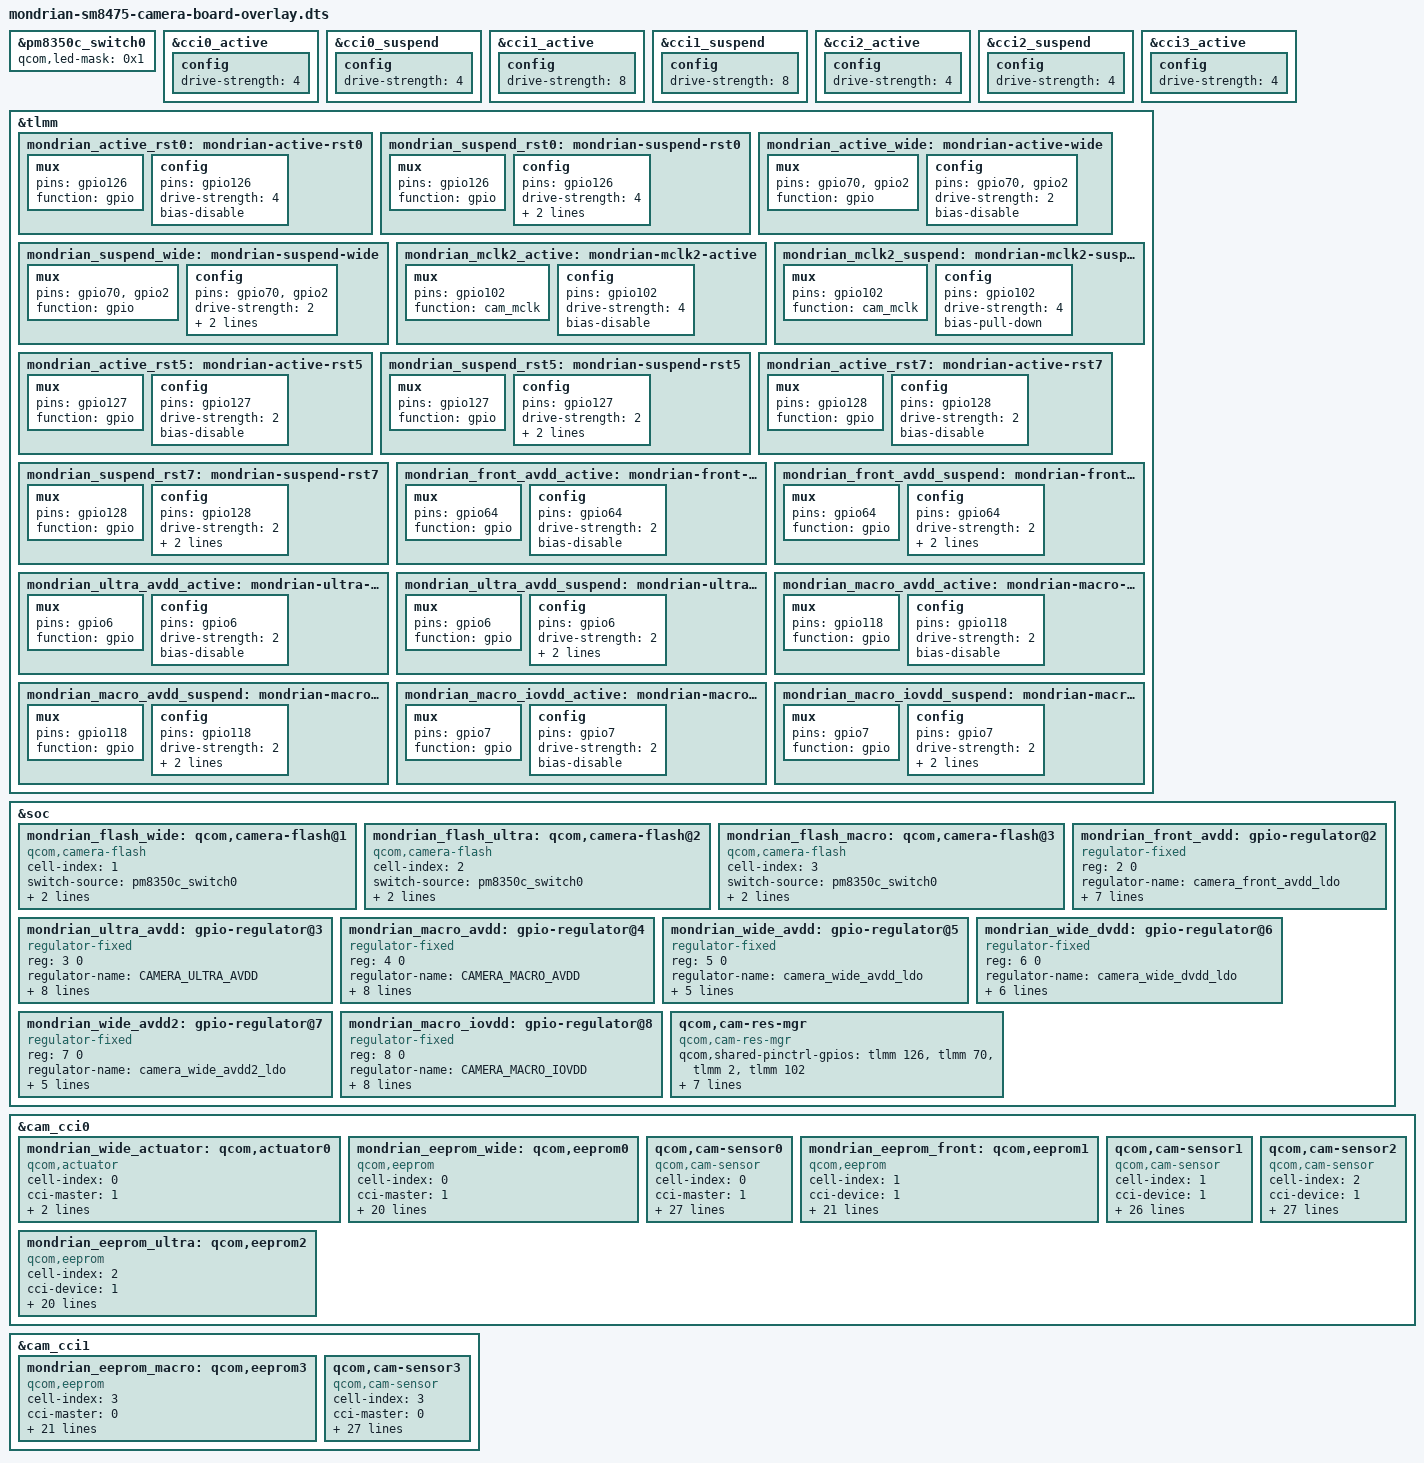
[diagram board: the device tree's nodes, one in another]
// SPDX-License-Identifier: GPL-2.0-only
/dts-v1/;
/plugin/;

#include <dt-bindings/clock/qcom,camcc-waipio.h>

/* Diagnostic board layer, applied after the OEM mondrian board and Cape camera
 * controllers. The board routes and evidence are documented in
 * docs/MONDRIAN_STOCK_CAMERA_ROUTING.md.
 */

&pm8350c_switch0 {
	qcom,led-mask = <0x1>;
};

&cci0_active {
	config {
		drive-strength = <4>;
	};
};

&cci0_suspend {
	config {
		drive-strength = <4>;
	};
};

&cci1_active {
	config {
		drive-strength = <8>;
	};
};

&cci1_suspend {
	config {
		drive-strength = <8>;
	};
};

&cci2_active {
	config {
		drive-strength = <4>;
	};
};

&cci2_suspend {
	config {
		drive-strength = <4>;
	};
};

&cci3_active {
	config {
		drive-strength = <4>;
	};
};

&tlmm {
	mondrian_active_rst0: mondrian-active-rst0 {
		mux {
			pins = "gpio126";
			function = "gpio";
		};
		config {
			pins = "gpio126";
			drive-strength = <4>;
			bias-disable;
		};
	};

	mondrian_suspend_rst0: mondrian-suspend-rst0 {
		mux {
			pins = "gpio126";
			function = "gpio";
		};
		config {
			pins = "gpio126";
			drive-strength = <4>;
			bias-pull-down;
			output-low;
		};
	};

	mondrian_active_wide: mondrian-active-wide {
		mux {
			pins = "gpio70", "gpio2";
			function = "gpio";
		};
		config {
			pins = "gpio70", "gpio2";
			drive-strength = <2>;
			bias-disable;
		};
	};

	mondrian_suspend_wide: mondrian-suspend-wide {
		mux {
			pins = "gpio70", "gpio2";
			function = "gpio";
		};
		config {
			pins = "gpio70", "gpio2";
			drive-strength = <2>;
			bias-pull-down;
			output-low;
		};
	};

	mondrian_mclk2_active: mondrian-mclk2-active {
		mux {
			pins = "gpio102";
			function = "cam_mclk";
		};
		config {
			pins = "gpio102";
			drive-strength = <4>;
			bias-disable;
		};
	};

	mondrian_mclk2_suspend: mondrian-mclk2-suspend {
		mux {
			pins = "gpio102";
			function = "cam_mclk";
		};
		config {
			pins = "gpio102";
			drive-strength = <4>;
			bias-pull-down;
		};
	};

	mondrian_active_rst5: mondrian-active-rst5 {
		mux {
			pins = "gpio127";
			function = "gpio";
		};
		config {
			pins = "gpio127";
			drive-strength = <2>;
			bias-disable;
		};
	};

	mondrian_suspend_rst5: mondrian-suspend-rst5 {
		mux {
			pins = "gpio127";
			function = "gpio";
		};
		config {
			pins = "gpio127";
			drive-strength = <2>;
			bias-pull-down;
			output-low;
		};
	};

	mondrian_active_rst7: mondrian-active-rst7 {
		mux {
			pins = "gpio128";
			function = "gpio";
		};
		config {
			pins = "gpio128";
			drive-strength = <2>;
			bias-disable;
		};
	};

	mondrian_suspend_rst7: mondrian-suspend-rst7 {
		mux {
			pins = "gpio128";
			function = "gpio";
		};
		config {
			pins = "gpio128";
			drive-strength = <2>;
			bias-pull-down;
			output-low;
		};
	};

	mondrian_front_avdd_active: mondrian-front-avdd-active {
		mux {
			pins = "gpio64";
			function = "gpio";
		};
		config {
			pins = "gpio64";
			drive-strength = <2>;
			bias-disable;
		};
	};

	mondrian_front_avdd_suspend: mondrian-front-avdd-suspend {
		mux {
			pins = "gpio64";
			function = "gpio";
		};
		config {
			pins = "gpio64";
			drive-strength = <2>;
			bias-pull-down;
			output-low;
		};
	};

	mondrian_ultra_avdd_active: mondrian-ultra-avdd-active {
		mux {
			pins = "gpio6";
			function = "gpio";
		};
		config {
			pins = "gpio6";
			drive-strength = <2>;
			bias-disable;
		};
	};

	mondrian_ultra_avdd_suspend: mondrian-ultra-avdd-suspend {
		mux {
			pins = "gpio6";
			function = "gpio";
		};
		config {
			pins = "gpio6";
			drive-strength = <2>;
			bias-pull-down;
			output-low;
		};
	};

	mondrian_macro_avdd_active: mondrian-macro-avdd-active {
		mux {
			pins = "gpio118";
			function = "gpio";
		};
		config {
			pins = "gpio118";
			drive-strength = <2>;
			bias-disable;
		};
	};

	mondrian_macro_avdd_suspend: mondrian-macro-avdd-suspend {
		mux {
			pins = "gpio118";
			function = "gpio";
		};
		config {
			pins = "gpio118";
			drive-strength = <2>;
			bias-pull-down;
			output-low;
		};
	};

	/* Macro IOVDD switch on GPIO 7, as in the stock OS3 mondrian DT. */
	mondrian_macro_iovdd_active: mondrian-macro-iovdd-active {
		mux {
			pins = "gpio7";
			function = "gpio";
		};
		config {
			pins = "gpio7";
			drive-strength = <2>;
			bias-disable;
		};
	};

	mondrian_macro_iovdd_suspend: mondrian-macro-iovdd-suspend {
		mux {
			pins = "gpio7";
			function = "gpio";
		};
		config {
			pins = "gpio7";
			drive-strength = <2>;
			bias-pull-down;
			output-low;
		};
	};
};

&soc {
	mondrian_flash_wide: qcom,camera-flash@1 {
		compatible = "qcom,camera-flash";
		cell-index = <1>;
		switch-source = <&pm8350c_switch0>;
		flash-source = <&pm8350c_flash0>;
		torch-source = <&pm8350c_torch0>;
		status = "ok";
	};

	mondrian_flash_ultra: qcom,camera-flash@2 {
		compatible = "qcom,camera-flash";
		cell-index = <2>;
		switch-source = <&pm8350c_switch0>;
		flash-source = <&pm8350c_flash0>;
		torch-source = <&pm8350c_torch0>;
		status = "ok";
	};

	mondrian_flash_macro: qcom,camera-flash@3 {
		compatible = "qcom,camera-flash";
		cell-index = <3>;
		switch-source = <&pm8350c_switch0>;
		flash-source = <&pm8350c_flash0>;
		torch-source = <&pm8350c_torch0>;
		status = "ok";
	};

	mondrian_front_avdd: gpio-regulator@2 {
		compatible = "regulator-fixed";
		reg = <2 0>;
		regulator-name = "camera_front_avdd_ldo";
		regulator-min-microvolt = <2800000>;
		regulator-max-microvolt = <2800000>;
		regulator-enable-ramp-delay = <100>;
		gpio = <&tlmm 64 0>;
		enable-active-high;
		pinctrl-names = "front_avdd_active", "front_avdd_suspend";
		pinctrl-0 = <&mondrian_front_avdd_active>, <&mondrian_front_avdd_suspend>;
	};

	mondrian_ultra_avdd: gpio-regulator@3 {
		compatible = "regulator-fixed";
		reg = <3 0>;
		regulator-name = "CAMERA_ULTRA_AVDD";
		regulator-min-microvolt = <2800000>;
		regulator-max-microvolt = <2800000>;
		regulator-enable-ramp-delay = <100>;
		vin-supply = <&BOB>;
		gpio = <&tlmm 6 0>;
		enable-active-high;
		pinctrl-names = "ultra_avdd_active", "ultra_avdd_suspend";
		pinctrl-0 = <&mondrian_ultra_avdd_active>, <&mondrian_ultra_avdd_suspend>;
	};

	mondrian_macro_avdd: gpio-regulator@4 {
		compatible = "regulator-fixed";
		reg = <4 0>;
		regulator-name = "CAMERA_MACRO_AVDD";
		regulator-min-microvolt = <2800000>;
		regulator-max-microvolt = <2800000>;
		regulator-enable-ramp-delay = <100>;
		vin-supply = <&BOB>;
		gpio = <&tlmm 118 0>;
		enable-active-high;
		pinctrl-names = "macro_avdd_active", "macro_avdd_suspend";
		pinctrl-0 = <&mondrian_macro_avdd_active>, <&mondrian_macro_avdd_suspend>;
	};

	mondrian_wide_avdd: gpio-regulator@5 {
		compatible = "regulator-fixed";
		reg = <5 0>;
		regulator-name = "camera_wide_avdd_ldo";
		regulator-min-microvolt = <2800000>;
		regulator-max-microvolt = <2800000>;
		regulator-enable-ramp-delay = <100>;
		gpio = <&tlmm 70 0>;
		enable-active-high;
	};

	mondrian_wide_dvdd: gpio-regulator@6 {
		compatible = "regulator-fixed";
		reg = <6 0>;
		regulator-name = "camera_wide_dvdd_ldo";
		regulator-min-microvolt = <1100000>;
		regulator-max-microvolt = <1100000>;
		regulator-enable-ramp-delay = <100>;
		vin-supply = <&S12B>;
		gpio = <&tlmm 2 0>;
		enable-active-high;
	};

	mondrian_wide_avdd2: gpio-regulator@7 {
		compatible = "regulator-fixed";
		reg = <7 0>;
		regulator-name = "camera_wide_avdd2_ldo";
		regulator-min-microvolt = <1860000>;
		regulator-max-microvolt = <1860000>;
		regulator-enable-ramp-delay = <100>;
		gpio = <&tlmm 97 0>;
		enable-active-high;
	};

	/*
	 * CAMERA_MACRO_IOVDD (GPIO 7 switch from BOB), as in the stock OS3
	 * mondrian DT. No sensor uses it (the macro sensor's cam_vio is
	 * pm8350c L1), so the regulator core turns it off as unused at late
	 * init, exactly as on stock, instead of leaving GPIO 7 as the
	 * bootloader set it.
	 */
	mondrian_macro_iovdd: gpio-regulator@8 {
		compatible = "regulator-fixed";
		reg = <8 0>;
		regulator-name = "CAMERA_MACRO_IOVDD";
		regulator-min-microvolt = <1800000>;
		regulator-max-microvolt = <1800000>;
		regulator-enable-ramp-delay = <100>;
		vin-supply = <&BOB>;
		gpio = <&tlmm 7 0>;
		enable-active-high;
		pinctrl-names = "macro_iovdd_active", "macro_iovdd_suspend";
		pinctrl-0 = <&mondrian_macro_iovdd_active>, <&mondrian_macro_iovdd_suspend>;
	};

	/* GPIO specifiers are resolved by the camera resource manager at probe. */
	qcom,cam-res-mgr {
		compatible = "qcom,cam-res-mgr";
		qcom,shared-pinctrl-gpios = <&tlmm 126 0>, <&tlmm 70 0>, <&tlmm 2 0>, <&tlmm 102 0>;
		shared-pctrl-gpio-names = "cam_wide", "cam_wide", "cam_wide", "cam_wide";
		pinctrl-names = "cam_wide_active", "cam_wide_suspend";
		pinctrl-0 = <&mondrian_active_rst0>, <&mondrian_active_wide>, <&mondrian_mclk2_active>;
		pinctrl-1 = <&mondrian_suspend_rst0>, <&mondrian_suspend_wide>, <&mondrian_mclk2_suspend>;
		status = "ok";
	};
};

&cam_cci0 {
	mondrian_wide_actuator: qcom,actuator0 {
		compatible = "qcom,actuator";
		cell-index = <0>;
		cci-master = <1>;
		regulator-names = "cam_vdig";
		cam_vdig-supply = <&mondrian_wide_dvdd>;
	};

	mondrian_eeprom_wide: qcom,eeprom0 {
		compatible = "qcom,eeprom";
		cell-index = <0>;
		cci-master = <1>;
		regulator-names = "cam_vdig", "cam_clk", "cam_vana", "cam_v_custom1";
		cam_vdig-supply = <&mondrian_wide_dvdd>;
		cam_vana-supply = <&mondrian_wide_avdd>;
		cam_v_custom1-supply = <&mondrian_wide_avdd2>;
		cam_clk-supply = <&cam_cc_titan_top_gdsc>;
		rgltr-cntrl-support;
		rgltr-min-voltage = <1100000 0 2800000 1860000>;
		rgltr-max-voltage = <1100000 0 2800000 1860000>;
		rgltr-load-current = <680000 0 103000 50000>;
		clock-names = "cam_clk";
		clocks = <&clock_camcc CAM_CC_MCLK2_CLK>;
		clock-rates = <19200000>;
		clock-cntl-level = "nominal";
		use-shared-clk;
		gpios = <&tlmm 102 0>, <&tlmm 126 0>;
		gpio-no-mux = <0>;
		gpio-reset = <1>;
		gpio-req-tbl-num = <0 1>;
		gpio-req-tbl-flags = <1 0>;
		gpio-req-tbl-label = "CAMIF_MCLK2", "CAM_RESET0";
		status = "ok";
	};

	qcom,cam-sensor0 {
		compatible = "qcom,cam-sensor";
		cell-index = <0>;
		cci-master = <1>;
		csiphy-sd-index = <2>;
		eeprom-src = <&mondrian_eeprom_wide>;
		actuator-src = <&mondrian_wide_actuator>;
		led-flash-src = <&mondrian_flash_wide>;
		sensor-position-roll = <90>;
		sensor-position-pitch = <0>;
		sensor-position-yaw = <180>;
		regulator-names = "cam_vdig", "cam_clk", "cam_vana", "cam_v_custom1";
		cam_vdig-supply = <&mondrian_wide_dvdd>;
		cam_vana-supply = <&mondrian_wide_avdd>;
		cam_v_custom1-supply = <&mondrian_wide_avdd2>;
		cam_clk-supply = <&cam_cc_titan_top_gdsc>;
		rgltr-cntrl-support;
		rgltr-min-voltage = <1100000 0 2800000 1860000>;
		rgltr-max-voltage = <1100000 0 2800000 1860000>;
		rgltr-load-current = <680000 0 103000 50000>;
		clock-names = "cam_clk";
		clocks = <&clock_camcc CAM_CC_MCLK2_CLK>;
		clock-rates = <19200000>;
		clock-cntl-level = "nominal";
		use-shared-clk;
		gpios = <&tlmm 102 0>, <&tlmm 126 0>;
		gpio-no-mux = <0>;
		gpio-reset = <1>;
		gpio-req-tbl-num = <0 1>;
		gpio-req-tbl-flags = <1 0>;
		gpio-req-tbl-label = "CAMIF_MCLK2", "CAM_RESET0";
		status = "ok";
	};

	mondrian_eeprom_front: qcom,eeprom1 {
		compatible = "qcom,eeprom";
		cell-index = <1>;
		cci-device = <1>;
		cci-master = <0>;
		regulator-names = "cam_clk", "cam_vana";
		cam_vana-supply = <&mondrian_front_avdd>;
		cam_clk-supply = <&cam_cc_titan_top_gdsc>;
		rgltr-cntrl-support;
		rgltr-min-voltage = <0 2800000>;
		rgltr-max-voltage = <0 2800000>;
		rgltr-load-current = <0 35000>;
		clock-names = "cam_clk";
		clocks = <&clock_camcc CAM_CC_MCLK5_CLK>;
		clock-rates = <19200000>;
		clock-cntl-level = "nominal";
		gpios = <&tlmm 105 0>, <&tlmm 127 0>;
		gpio-no-mux = <0>;
		gpio-reset = <1>;
		gpio-req-tbl-num = <0 1>;
		gpio-req-tbl-flags = <1 0>;
		gpio-req-tbl-label = "CAMIF_MCLK5", "CAM_RESET5";
		pinctrl-names = "cam_default", "cam_suspend";
		pinctrl-0 = <&cam_sensor_mclk5_active>, <&mondrian_active_rst5>;
		pinctrl-1 = <&cam_sensor_mclk5_suspend>, <&mondrian_suspend_rst5>;
		status = "ok";
	};

	qcom,cam-sensor1 {
		compatible = "qcom,cam-sensor";
		cell-index = <1>;
		cci-device = <1>;
		cci-master = <0>;
		csiphy-sd-index = <4>;
		eeprom-src = <&mondrian_eeprom_front>;
		sensor-position-roll = <270>;
		sensor-position-pitch = <0>;
		sensor-position-yaw = <0>;
		regulator-names = "cam_clk", "cam_vana";
		cam_vana-supply = <&mondrian_front_avdd>;
		cam_clk-supply = <&cam_cc_titan_top_gdsc>;
		rgltr-cntrl-support;
		rgltr-min-voltage = <0 2800000>;
		rgltr-max-voltage = <0 2800000>;
		rgltr-load-current = <0 35000>;
		clock-names = "cam_clk";
		clocks = <&clock_camcc CAM_CC_MCLK5_CLK>;
		clock-rates = <19200000>;
		clock-cntl-level = "nominal";
		gpios = <&tlmm 105 0>, <&tlmm 127 0>;
		gpio-no-mux = <0>;
		gpio-reset = <1>;
		gpio-req-tbl-num = <0 1>;
		gpio-req-tbl-flags = <1 0>;
		gpio-req-tbl-label = "CAMIF_MCLK5", "CAM_RESET5";
		pinctrl-names = "cam_default", "cam_suspend";
		pinctrl-0 = <&cam_sensor_mclk5_active>, <&mondrian_active_rst5>;
		pinctrl-1 = <&cam_sensor_mclk5_suspend>, <&mondrian_suspend_rst5>;
		status = "ok";
	};

	/* P24C64F uses WL2866D AVDD1. GPIO index 0 is OV08D10 MCLK1. */
	mondrian_eeprom_ultra: qcom,eeprom2 {
		compatible = "qcom,eeprom";
		cell-index = <2>;
		cci-device = <1>;
		cci-master = <0>;
		regulator-names = "cam_vana", "cam_clk";
		cam_vana-supply = <&mondrian_ultra_avdd>;
		cam_clk-supply = <&cam_cc_titan_top_gdsc>;
		rgltr-cntrl-support;
		rgltr-min-voltage = <2800000 0>;
		rgltr-max-voltage = <2800000 0>;
		rgltr-load-current = <35000 0>;
		clock-names = "cam_clk";
		clocks = <&clock_camcc CAM_CC_MCLK1_CLK>;
		clock-rates = <19200000>;
		clock-cntl-level = "nominal";
		gpios = <&tlmm 101 0>, <&tlmm 24 0>;
		gpio-no-mux = <0>;
		gpio-req-tbl-num = <0 1>;
		gpio-req-tbl-flags = <1 0>;
		gpio-req-tbl-label = "CAMIF_MCLK1", "CAM_RESET1";
		pinctrl-names = "cam_default", "cam_suspend";
		pinctrl-0 = <&cam_sensor_mclk1_active>, <&cam_sensor_active_rst1>;
		pinctrl-1 = <&cam_sensor_mclk1_suspend>, <&cam_sensor_suspend_rst1>;
		status = "ok";
	};

	qcom,cam-sensor2 {
		compatible = "qcom,cam-sensor";
		cell-index = <2>;
		cci-device = <1>;
		cci-master = <0>;
		csiphy-sd-index = <1>;
		eeprom-src = <&mondrian_eeprom_ultra>;
		led-flash-src = <&mondrian_flash_ultra>;
		sensor-position-roll = <90>;
		sensor-position-pitch = <0>;
		sensor-position-yaw = <180>;
		regulator-names = "cam_clk", "cam_vana";
		cam_vana-supply = <&mondrian_ultra_avdd>;
		cam_clk-supply = <&cam_cc_titan_top_gdsc>;
		rgltr-cntrl-support;
		rgltr-min-voltage = <0 2800000>;
		rgltr-max-voltage = <0 2800000>;
		rgltr-load-current = <0 35000>;
		clock-names = "cam_clk";
		clocks = <&clock_camcc CAM_CC_MCLK1_CLK>;
		clock-rates = <19200000>;
		clock-cntl-level = "nominal";
		gpios = <&tlmm 101 0>, <&tlmm 24 0>;
		gpio-no-mux = <0>;
		gpio-reset = <1>;
		gpio-req-tbl-num = <0 1>;
		gpio-req-tbl-flags = <1 0>;
		gpio-req-tbl-label = "CAMIF_MCLK1", "CAM_RESET1";
		pinctrl-names = "cam_default", "cam_suspend";
		pinctrl-0 = <&cam_sensor_mclk1_active>, <&cam_sensor_active_rst1>;
		pinctrl-1 = <&cam_sensor_mclk1_suspend>, <&cam_sensor_suspend_rst1>;
		status = "ok";
	};
};

&cam_cci1 {
	mondrian_eeprom_macro: qcom,eeprom3 {
		compatible = "qcom,eeprom";
		cell-index = <3>;
		cci-master = <0>;
		regulator-names = "cam_vio", "cam_clk";
		cam_vana-supply = <&mondrian_macro_avdd>;
		cam_vio-supply = <&L1C>;
		cam_clk-supply = <&cam_cc_titan_top_gdsc>;
		rgltr-cntrl-support;
		rgltr-min-voltage = <1800000 0>;
		rgltr-max-voltage = <1800000 0>;
		rgltr-load-current = <5000 0>;
		clock-names = "cam_clk";
		clocks = <&clock_camcc CAM_CC_MCLK0_CLK>;
		clock-rates = <19200000>;
		clock-cntl-level = "nominal";
		gpios = <&tlmm 100 0>, <&tlmm 128 0>;
		gpio-no-mux = <0>;
		gpio-reset = <1>;
		gpio-req-tbl-num = <0 1>;
		gpio-req-tbl-flags = <1 0>;
		gpio-req-tbl-label = "CAMIF_MCLK0", "CAM_RESET7";
		pinctrl-names = "cam_default", "cam_suspend";
		pinctrl-0 = <&cam_sensor_mclk0_active>, <&mondrian_active_rst7>;
		pinctrl-1 = <&cam_sensor_mclk0_suspend>, <&mondrian_suspend_rst7>;
		status = "ok";
	};

	qcom,cam-sensor3 {
		compatible = "qcom,cam-sensor";
		cell-index = <3>;
		cci-master = <0>;
		csiphy-sd-index = <0>;
		eeprom-src = <&mondrian_eeprom_macro>;
		led-flash-src = <&mondrian_flash_macro>;
		sensor-position-roll = <90>;
		sensor-position-pitch = <0>;
		sensor-position-yaw = <180>;
		regulator-names = "cam_vio", "cam_clk", "cam_vana";
		cam_vana-supply = <&mondrian_macro_avdd>;
		cam_vio-supply = <&L1C>;
		cam_clk-supply = <&cam_cc_titan_top_gdsc>;
		rgltr-cntrl-support;
		rgltr-min-voltage = <1800000 0 2800000>;
		rgltr-max-voltage = <1800000 0 2800000>;
		rgltr-load-current = <5000 0 35000>;
		clock-names = "cam_clk";
		clocks = <&clock_camcc CAM_CC_MCLK0_CLK>;
		clock-rates = <19200000>;
		clock-cntl-level = "nominal";
		gpios = <&tlmm 100 0>, <&tlmm 128 0>;
		gpio-no-mux = <0>;
		gpio-reset = <1>;
		gpio-req-tbl-num = <0 1>;
		gpio-req-tbl-flags = <1 0>;
		gpio-req-tbl-label = "CAMIF_MCLK0", "CAM_RESET7";
		pinctrl-names = "cam_default", "cam_suspend";
		pinctrl-0 = <&cam_sensor_mclk0_active>, <&mondrian_active_rst7>;
		pinctrl-1 = <&cam_sensor_mclk0_suspend>, <&mondrian_suspend_rst7>;
		status = "ok";
	};
};
